VERSION ""

NS_ :

BS_:

BU_: BMSLV MCU TCU

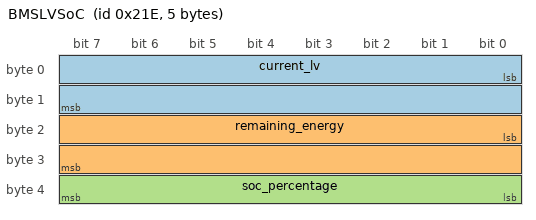
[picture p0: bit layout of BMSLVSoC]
BO_ 542 BMSLVSoC: 5 BMSLV
 SG_ current_lv : 0|16@1- (0.01,0) [0|0] "A" MCU,TCU
 SG_ remaining_energy : 16|16@1+ (0.1,0) [0|648] "Wh" MCU,TCU
 SG_ soc_percentage : 32|8@1+ (1,0) [0|100] "%" MCU,TCU
